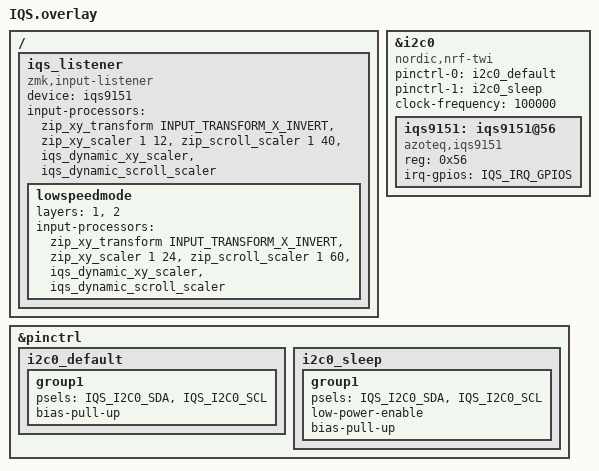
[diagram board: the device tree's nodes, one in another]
&i2c0 {
    status = "okay";
    compatible = "nordic,nrf-twi";
    pinctrl-0 = <&i2c0_default>;
    pinctrl-1 = <&i2c0_sleep>;
    pinctrl-names = "default", "sleep";
    clock-frequency = <100000>;

    iqs9151: iqs9151@56 {
        compatible = "azoteq,iqs9151";
        reg = <0x56>;
        status = "okay";
        irq-gpios = IQS_IRQ_GPIOS;
    };
};

&pinctrl {
    i2c0_default: i2c0_default {
        group1 {
            psels = <IQS_I2C0_SDA>,
                    <IQS_I2C0_SCL>;
            bias-pull-up;
        };
    };

    i2c0_sleep: i2c0_sleep {
        group1 {
            psels = <IQS_I2C0_SDA>,
                    <IQS_I2C0_SCL>;
            low-power-enable;
            bias-pull-up;
        };
    };
};

/ {
    iqs_listener: iqs_listener {
        compatible = "zmk,input-listener";
        status = "okay";
        device = <&iqs9151>;
        input-processors = <&zip_xy_transform INPUT_TRANSFORM_X_INVERT>,
                           <&zip_xy_scaler 1 12>,
                           <&zip_scroll_scaler 1 40>,
                           <&iqs_dynamic_xy_scaler>,
                           <&iqs_dynamic_scroll_scaler>;

        lowspeedmode {
            layers = <1>, <2>;
            input-processors = <&zip_xy_transform INPUT_TRANSFORM_X_INVERT>,
                               <&zip_xy_scaler 1 24>,
                               <&zip_scroll_scaler 1 60>,
                               <&iqs_dynamic_xy_scaler>,
                               <&iqs_dynamic_scroll_scaler>;
        };
    };
};
